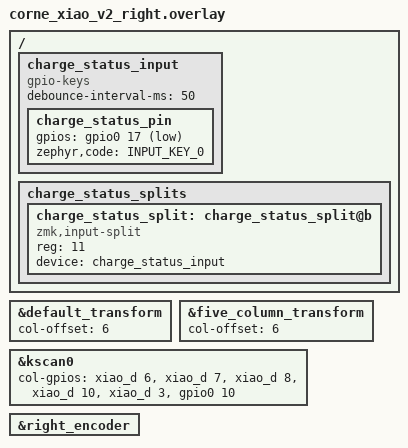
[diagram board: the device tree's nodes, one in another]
#include "corne_xiao_v2.dtsi"
#include <zephyr/dt-bindings/input/input-event-codes.h>

/ {
    charge_status_input: charge_status_input {
        compatible = "gpio-keys";
        debounce-interval-ms = <50>;

        charge_status_pin: charge_status_pin {
            gpios = <&gpio0 17 (GPIO_ACTIVE_LOW | GPIO_PULL_UP)>;
            zephyr,code = <INPUT_KEY_0>;
        };
    };

    charge_status_splits {
        #address-cells = <1>;
        #size-cells = <0>;

        charge_status_split: charge_status_split@b {
            compatible = "zmk,input-split";
            reg = <11>;
            device = <&charge_status_input>;
        };
    };
};

&default_transform {
    col-offset = <6>;
};

&five_column_transform {
    col-offset = <6>;
};

&kscan0 {
    col-gpios
        = <&xiao_d 6 GPIO_ACTIVE_HIGH>
        , <&xiao_d 7 GPIO_ACTIVE_HIGH> 
        , <&xiao_d 8 GPIO_ACTIVE_HIGH>
        , <&xiao_d 10 GPIO_ACTIVE_HIGH>
        , <&xiao_d 3 GPIO_ACTIVE_HIGH>
        , <&gpio0 10 GPIO_ACTIVE_HIGH>
        ;
};

&right_encoder {
    status = "okay";
};
